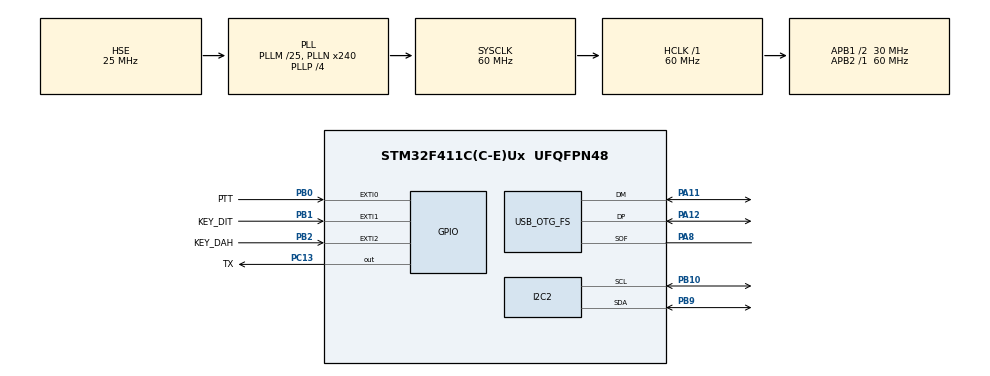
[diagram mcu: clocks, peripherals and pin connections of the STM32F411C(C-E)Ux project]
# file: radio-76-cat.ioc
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Mcu.Family=STM32F4
Mcu.Name=STM32F411C(C-E)Ux
Mcu.Package=UFQFPN48
NVIC.EXTI0_IRQn=true\:0\:0\:false\:false\:true\:true\:true
NVIC.EXTI1_IRQn=true\:0\:0\:false\:false\:true\:true\:true
NVIC.EXTI2_IRQn=true\:0\:0\:false\:false\:true\:true\:true
NVIC.OTG_FS_IRQn=true\:0\:0\:false\:false\:true\:false\:true
NVIC.PriorityGroup=NVIC_PRIORITYGROUP_4
PA11.Mode=Device_Only
PA11.Signal=USB_OTG_FS_DM
PA12.GPIO_PuPd=GPIO_NOPULL
PA12.Mode=Device_Only
PA12.Signal=USB_OTG_FS_DP
PA13.Mode=Serial_Wire
PA13.Signal=SYS_JTMS-SWDIO
PA14.Mode=Serial_Wire
PA14.Signal=SYS_JTCK-SWCLK
PA8.Mode=Activate_SOF_FS
PA8.Signal=USB_OTG_FS_SOF
PB0.GPIO_Label=PTT
PB0.Signal=GPXTI0
PB1.GPIO_Label=KEY_DIT
PB1.Signal=GPXTI1
PB10.Mode=I2C
PB10.Signal=I2C2_SCL
PB2.GPIO_Label=KEY_DAH
PB2.Signal=GPXTI2
PB9.Mode=I2C
PB9.Signal=I2C2_SDA
PC13-ANTI_TAMP.GPIO_Label=TX
PC13-ANTI_TAMP.PinState=GPIO_PIN_SET
PC13-ANTI_TAMP.Signal=GPIO_Output
PH0\ -\ OSC_IN.Mode=HSE-External-Oscillator
PH0\ -\ OSC_IN.Signal=RCC_OSC_IN
PH1\ -\ OSC_OUT.Mode=HSE-External-Oscillator
PH1\ -\ OSC_OUT.Signal=RCC_OSC_OUT
ProjectManager.HeapSize=0x200
ProjectManager.StackSize=0x400
ProjectManager.TargetToolchain=STM32CubeIDE
RCC.48MHZClocksFreq_Value=48000000
RCC.AHBFreq_Value=60000000
RCC.APB1CLKDivider=RCC_HCLK_DIV2
RCC.APB1Freq_Value=30000000
RCC.APB1TimFreq_Value=60000000
RCC.APB2Freq_Value=60000000
RCC.APB2TimFreq_Value=60000000
RCC.CortexFreq_Value=60000000
RCC.HCLKFreq_Value=60000000
RCC.HSE_VALUE=25000000
RCC.HSI_VALUE=16000000
RCC.LSE_VALUE=32768
RCC.PLLM=25
RCC.PLLN=240
RCC.PLLP=RCC_PLLP_DIV4
RCC.PLLQ=5
RCC.SYSCLKFreq_VALUE=60000000
RCC.SYSCLKSource=RCC_SYSCLKSOURCE_PLLCLK
RCC.VCOOutputFreq_Value=240000000
USB_DEVICE.APP_RX_DATA_SIZE=64
USB_DEVICE.APP_TX_DATA_SIZE=64
USB_DEVICE.CLASS_NAME_FS=CDC
USB_DEVICE.CONFIGURATION_STRING_CDC_FS=Radio-76 Config
USB_DEVICE.INTERFACE_STRING_CDC_FS=Radio-76 CAT Interface
USB_DEVICE.PID_CDC_FS=22330
USB_DEVICE.PRODUCT_STRING_CDC_FS=Radio-76 TRX
USB_DEVICE.USBD_MAX_NUM_INTERFACES=2
USB_DEVICE.VirtualMode=Cdc
USB_DEVICE.VirtualModeFS=Cdc_FS
USB_OTG_FS.VirtualMode=Device_Only
VP_USB_DEVICE_VS_USB_DEVICE_CDC_FS.Mode=CDC_FS
board=custom

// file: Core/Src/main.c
/* USER CODE BEGIN Header */
/**
  ******************************************************************************
  * @file           : main.c
  * @brief          : Main program body
  ******************************************************************************
  * @attention
  *
  * <h2><center>&copy; Copyright (c) 2021 STMicroelectronics.
  * All rights reserved.</center></h2>
  *
  * This software component is licensed by ST under BSD 3-Clause license,
  * the "License"; You may not use this file except in compliance with the
  * License. You may obtain a copy of the License at:
  *                        opensource.org/licenses/BSD-3-Clause
  *
  ******************************************************************************
  */
/* USER CODE END Header */

#include "main.h"
#include "usb_device.h"

/* USER CODE BEGIN Includes */
#include "cat_if.h"
#include "ptt_if.h"

/* USER CODE END Includes */

I2C_HandleTypeDef hi2c2;

/* USER CODE BEGIN PV */
TRX_TypeDef trx;

/* USER CODE END PV */

void SystemClock_Config(void);
static void MX_GPIO_Init(void);
static void MX_I2C2_Init(void);

int main(void)
{

  /* MCU Configuration--------------------------------------------------------*/

  /* Reset of all peripherals, Initializes the Flash interface and the Systick. */
  HAL_Init();

  /* Configure the system clock */
  SystemClock_Config();

  /* Initialize all configured peripherals */
  MX_GPIO_Init();
  MX_USB_DEVICE_Init();
  MX_I2C2_Init();
  /* USER CODE BEGIN 2 */
  trx.sysclock = 0U;
  trx.systicks = 10U;

  trx.vfoa = 1900000U;
  trx.vfob = 1900000U;

  PTT_Init ();

  /* USER CODE END 2 */

  /* Infinite loop */
  /* USER CODE BEGIN WHILE */
  while (1)
  {
    CAT_Handler ();

    /* USER CODE END WHILE */

  }
}

void SystemClock_Config(void)
{
  RCC_OscInitTypeDef RCC_OscInitStruct = {0};
  RCC_ClkInitTypeDef RCC_ClkInitStruct = {0};

  /** Configure the main internal regulator output voltage
  */
  __HAL_RCC_PWR_CLK_ENABLE();
  __HAL_PWR_VOLTAGESCALING_CONFIG(PWR_REGULATOR_VOLTAGE_SCALE1);
  /** Initializes the CPU, AHB and APB busses clocks
  */
  RCC_OscInitStruct.OscillatorType = RCC_OSCILLATORTYPE_HSE;
  RCC_OscInitStruct.HSEState = RCC_HSE_ON;
  RCC_OscInitStruct.PLL.PLLState = RCC_PLL_ON;
  RCC_OscInitStruct.PLL.PLLSource = RCC_PLLSOURCE_HSE;
  RCC_OscInitStruct.PLL.PLLM = 25;
  RCC_OscInitStruct.PLL.PLLN = 240;
  RCC_OscInitStruct.PLL.PLLP = RCC_PLLP_DIV4;
  RCC_OscInitStruct.PLL.PLLQ = 5;
  if (HAL_RCC_OscConfig(&RCC_OscInitStruct) != HAL_OK)
  {
    Error_Handler();
  }
  /** Initializes the CPU, AHB and APB busses clocks
  */
  RCC_ClkInitStruct.ClockType = RCC_CLOCKTYPE_HCLK|RCC_CLOCKTYPE_SYSCLK
                              |RCC_CLOCKTYPE_PCLK1|RCC_CLOCKTYPE_PCLK2;
  RCC_ClkInitStruct.SYSCLKSource = RCC_SYSCLKSOURCE_PLLCLK;
  RCC_ClkInitStruct.AHBCLKDivider = RCC_SYSCLK_DIV1;
  RCC_ClkInitStruct.APB1CLKDivider = RCC_HCLK_DIV2;
  RCC_ClkInitStruct.APB2CLKDivider = RCC_HCLK_DIV1;

  if (HAL_RCC_ClockConfig(&RCC_ClkInitStruct, FLASH_LATENCY_1) != HAL_OK)
  {
    Error_Handler();
  }
}

static void MX_I2C2_Init(void)
{

  hi2c2.Instance = I2C2;
  hi2c2.Init.ClockSpeed = 100000;
  hi2c2.Init.DutyCycle = I2C_DUTYCYCLE_2;
  hi2c2.Init.OwnAddress1 = 0;
  hi2c2.Init.AddressingMode = I2C_ADDRESSINGMODE_7BIT;
  hi2c2.Init.DualAddressMode = I2C_DUALADDRESS_DISABLE;
  hi2c2.Init.OwnAddress2 = 0;
  hi2c2.Init.GeneralCallMode = I2C_GENERALCALL_DISABLE;
  hi2c2.Init.NoStretchMode = I2C_NOSTRETCH_DISABLE;
  if (HAL_I2C_Init(&hi2c2) != HAL_OK)
  {
    Error_Handler();
  }

}

static void MX_GPIO_Init(void)
{
  GPIO_InitTypeDef GPIO_InitStruct = {0};

  /* GPIO Ports Clock Enable */
  __HAL_RCC_GPIOC_CLK_ENABLE();
  __HAL_RCC_GPIOH_CLK_ENABLE();
  __HAL_RCC_GPIOB_CLK_ENABLE();
  __HAL_RCC_GPIOA_CLK_ENABLE();

  /*Configure GPIO pin Output Level */
  HAL_GPIO_WritePin(TX_GPIO_Port, TX_Pin, GPIO_PIN_SET);

  /*Configure GPIO pin : TX_Pin */
  GPIO_InitStruct.Pin = TX_Pin;
  GPIO_InitStruct.Mode = GPIO_MODE_OUTPUT_PP;
  GPIO_InitStruct.Pull = GPIO_NOPULL;
  GPIO_InitStruct.Speed = GPIO_SPEED_FREQ_LOW;
  HAL_GPIO_Init(TX_GPIO_Port, &GPIO_InitStruct);

  /*Configure GPIO pins : PTT_Pin KEY_DIT_Pin KEY_DAH_Pin */
  GPIO_InitStruct.Pin = PTT_Pin|KEY_DIT_Pin|KEY_DAH_Pin;
  GPIO_InitStruct.Mode = GPIO_MODE_IT_RISING;
  GPIO_InitStruct.Pull = GPIO_NOPULL;
  HAL_GPIO_Init(GPIOB, &GPIO_InitStruct);

  /* EXTI interrupt init*/
  HAL_NVIC_SetPriority(EXTI0_IRQn, 0, 0);
  HAL_NVIC_EnableIRQ(EXTI0_IRQn);

  HAL_NVIC_SetPriority(EXTI1_IRQn, 0, 0);
  HAL_NVIC_EnableIRQ(EXTI1_IRQn);

  HAL_NVIC_SetPriority(EXTI2_IRQn, 0, 0);
  HAL_NVIC_EnableIRQ(EXTI2_IRQn);

}

void Error_Handler(void)
{
}

/************************ (C) COPYRIGHT STMicroelectronics *****END OF FILE****/
